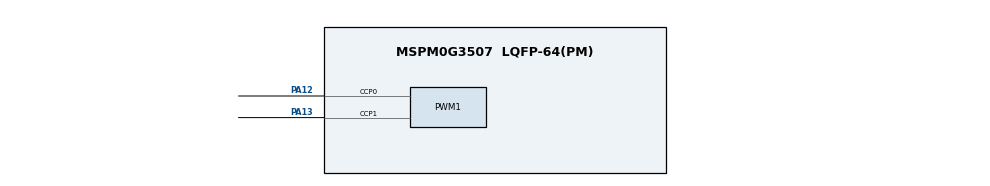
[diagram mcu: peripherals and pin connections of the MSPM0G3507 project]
//@cliArgs --device "MSPM0G350X" --package "LQFP-64(PM)" --part "Default"
//@v2CliArgs --device "MSPM0G3507" --package "LQFP-64(PM)"
// @cliArgs --board /ti/boards/LP_MSPM0G3507 --rtos nortos

/**
 * Import the modules used in this configuration.
 */
const GPIO   = scripting.addModule("/ti/driverlib/GPIO", {}, false);
const GPIO1  = GPIO.addInstance();
const GPIO2  = GPIO.addInstance();
const PWM    = scripting.addModule("/ti/driverlib/PWM", {}, false);
const PWM1   = PWM.addInstance();
const SYSCTL = scripting.addModule("/ti/driverlib/SYSCTL");

/**
 * Write custom configuration values to the imported modules.
 */

/* ========== TB6612 电机方向控制 GPIO ========== */
GPIO1.$name                         = "GPIO_MOTOR";
GPIO1.port                          = "PORTB";
GPIO1.associatedPins.create(4);
GPIO1.associatedPins[0].$name       = "AIN1";
GPIO1.associatedPins[0].assignedPin = "16";
GPIO1.associatedPins[1].$name       = "AIN2";
GPIO1.associatedPins[1].assignedPin = "13";
GPIO1.associatedPins[2].$name       = "BIN1";
GPIO1.associatedPins[2].assignedPin = "3";
GPIO1.associatedPins[3].$name       = "BIN2";
GPIO1.associatedPins[3].assignedPin = "2";

/* ========== S2 按键 + 编码器 GPIO ========== */
GPIO2.$name                              = "GPIO_SWITCHES";
GPIO2.associatedPins.create(5);
/* S2: PB21, 输入上拉 */
GPIO2.associatedPins[0].assignedPort     = "PORTB";
GPIO2.associatedPins[0].assignedPin      = "21";
GPIO2.associatedPins[0].$name            = "USER_SWITCH_1";
GPIO2.associatedPins[0].direction        = "INPUT";
GPIO2.associatedPins[0].internalResistor = "PULL_UP";
/* E1A: PA17, 编码器输入 */
GPIO2.associatedPins[1].assignedPort     = "PORTA";
GPIO2.associatedPins[1].assignedPin      = "17";
GPIO2.associatedPins[1].$name            = "ENC1A";
GPIO2.associatedPins[1].direction        = "INPUT";
GPIO2.associatedPins[1].internalResistor = "PULL_UP";
/* E1B: PA18 */
GPIO2.associatedPins[2].assignedPort     = "PORTA";
GPIO2.associatedPins[2].assignedPin      = "18";
GPIO2.associatedPins[2].$name            = "ENC1B";
GPIO2.associatedPins[2].direction        = "INPUT";
GPIO2.associatedPins[2].internalResistor = "PULL_UP";
/* E2A: PB6 */
GPIO2.associatedPins[3].assignedPort     = "PORTB";
GPIO2.associatedPins[3].assignedPin      = "6";
GPIO2.associatedPins[3].$name            = "ENC2A";
GPIO2.associatedPins[3].direction        = "INPUT";
GPIO2.associatedPins[3].internalResistor = "PULL_UP";
/* E2B: PB7 */
GPIO2.associatedPins[4].assignedPort     = "PORTB";
GPIO2.associatedPins[4].assignedPin      = "7";
GPIO2.associatedPins[4].$name            = "ENC2B";
GPIO2.associatedPins[4].direction        = "INPUT";
GPIO2.associatedPins[4].internalResistor = "PULL_UP";

/* 先启用 MFCLK，然后再配置 PWM */
const gate7  = system.clockTree["MFCLKGATE"];
gate7.enable = true;

/* ========== TB6612 电机 PWM 速度控制 ========== */
PWM1.$name                      = "PWM_MOTOR";
PWM1.clockSource                = "MFCLK";
PWM1.clockPrescale              = 1;
PWM1.timerCount                 = 199;
PWM1.peripheral.$assign         = "TIMG0";
PWM1.peripheral.ccp0Pin.$assign = "PA12";
PWM1.peripheral.ccp1Pin.$assign = "PA13";
PWM1.PWM_CHANNEL_0.$name        = "ti_driverlib_pwm_PWMTimerCC0";
PWM1.PWM_CHANNEL_0.dutyCycle    = 50;
PWM1.PWM_CHANNEL_1.$name        = "ti_driverlib_pwm_PWMTimerCC1";
PWM1.PWM_CHANNEL_1.dutyCycle    = 50;

const Board           = scripting.addModule("/ti/driverlib/Board", {}, false);
Board.configureUnused = true;

SYSCTL.MFCLKEn     = true;
SYSCTL.forceDefaultClkConfig = true;
SYSCTL.clockTreeEn  = true;
